# AT32UC3A4256S device description
Architecture: AVR32_UC3; Family: AVR UC3
Registers are 32-bit, read-write, reset 0x0 unless marked. A register's access mark holds for its fields unless they carry their own. Offsets are from the block's base; [hi:lo] are bit positions; {n}, {i} and the like mark numbered series.

## INTC — Interrupt Controller
Instances: INTC 0xFFFF0800
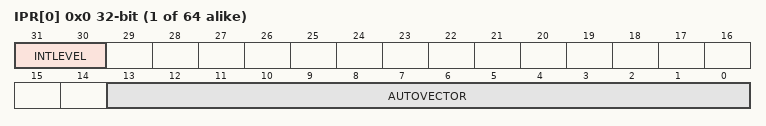
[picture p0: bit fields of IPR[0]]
{0x0+4i} IPR[{i}] (i=0..63) — Interrupt Priority Register
  [31:30] INTLEVEL — Interrupt Level
    {v}=INT{v} (v=0..3)
  [13:0] AUTOVECTOR — Handler offset
{0x100+4i} IRR[{i}] (i=0..63) ro — Interrupt Request Register
{0x200+4i} ICR[{i}] (i=0..3) ro — Interrupt Cause Register
  [5:0] CAUSE — Cause Group Number

## ADC — Analog to Digital Converter
Instances: ADC 0xffff3c00
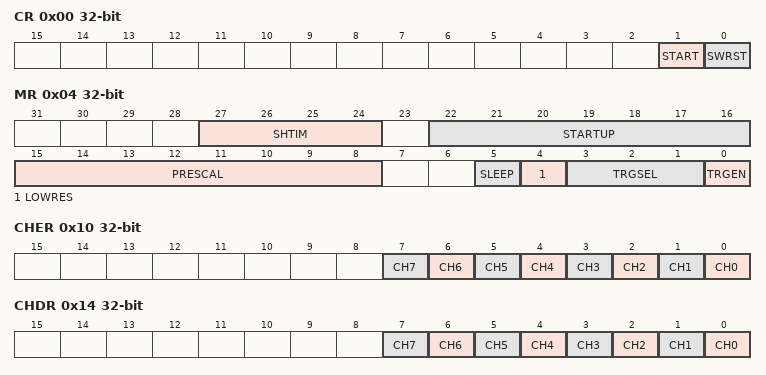
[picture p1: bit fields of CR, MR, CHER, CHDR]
0x00 CR wo reset not defined — Control Register
  [1] START — Start Conversion
  [0] SWRST — Software Reset
0x04 MR — Mode Register
  [27:24] SHTIM — Sample and Hold Time
  [22:16] STARTUP — Start Up Time
  [15:8] PRESCAL — Prescaler Rate Selection
  [5] SLEEP — Sleep Mode
  [4] LOWRES — Resolution
  [3:1] TRGSEL — Trigger Selection
  [0] TRGEN — Trigger Enable
0x10 CHER wo reset not defined — Channel Enable Register
  [n] CH{n} (n=0..7) — Channel {n} Enable
0x14 CHDR wo reset not defined — Channel Disable Register
  [n] CH{n} (n=0..7) — Channel {n} Disable
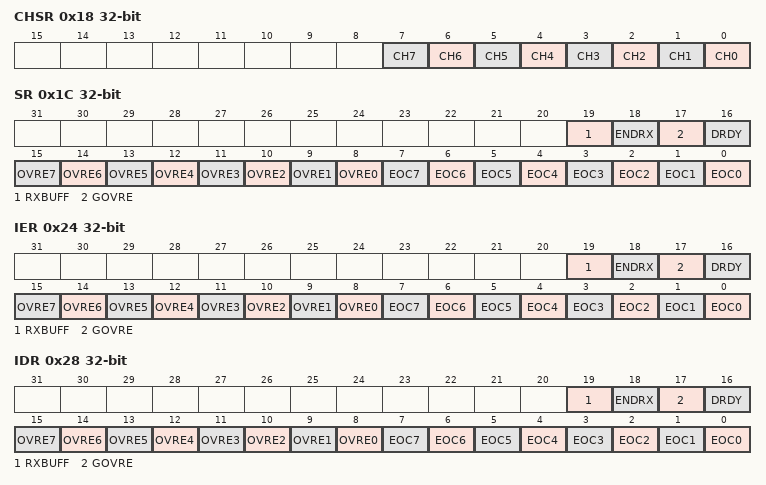
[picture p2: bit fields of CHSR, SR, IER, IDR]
0x18 CHSR ro — Channel Status Register
  [n] CH{n} (n=0..7)
0x1C SR ro reset not defined — Status Register
  [19] RXBUFF — RX Buffer Full
  [18] ENDRX — End of RX Buffer
  [17] GOVRE — General Overrun Error
  [16] DRDY — Data Ready
  [n+8] OVRE{n} (n=0..7) — Overrun Error {n}
  [n] EOC{n} (n=0..7) — End of Conversion {n}
0x20 LCDR ro reset not defined — Last Converted Data Register
  [9:0] LDATA — Last Data Converted
0x24 IER wo reset not defined — Interrupt Enable Register
  [19] RXBUFF — Receive Buffer Full Interrupt Enable
  [18] ENDRX — End of Receive Buffer Interrupt Enable
  [17] GOVRE — General Overrun Error Interrupt Enable
  [16] DRDY — Data Ready Interrupt Enable
  [n+8] OVRE{n} (n=0..7) — Overrun Error Interrupt Enable {n}
  [n] EOC{n} (n=0..7) — End of Conversion Interrupt Enable {n}
0x28 IDR wo reset not defined — Interrupt Disable Register
  [19] RXBUFF — Receive Buffer Full Interrupt Disable
  [18] ENDRX — End of Receive Buffer Interrupt Disable
  [17] GOVRE — General Overrun Interrupt Disable
  [16] DRDY — Data Ready Interrupt Disable
  [n+8] OVRE{n} (n=0..7) — Overrun Error Interrupt Disable {n}
  [n] EOC{n} (n=0..7) — End of Conversion Interrupt Disable {n}
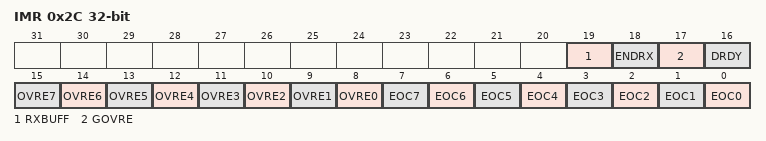
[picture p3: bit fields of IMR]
0x2C IMR ro — Interrupt Mask Register
  [19] RXBUFF — Receive Buffer Full Interrupt Mask
  [18] ENDRX — End of Receive Buffer Interrupt Mask
  [17] GOVRE — General Overrun Error Interrupt Mask
  [16] DRDY — Data Ready Interrupt Mask
  [n+8] OVRE{n} (n=0..7) — Overrun Error Interrupt Mask {n}
  [n] EOC{n} (n=0..7) — End of Conversion Interrupt Mask {n}
{0x30+4i} CDR{i} ro (i=0..7) — Channel Data Register {i}
  [9:0] DATA — Converted Data
0xFC VERSION ro reset not defined

## AES — Advanced Encryption Standard
Instances: AES 0xfffd0000
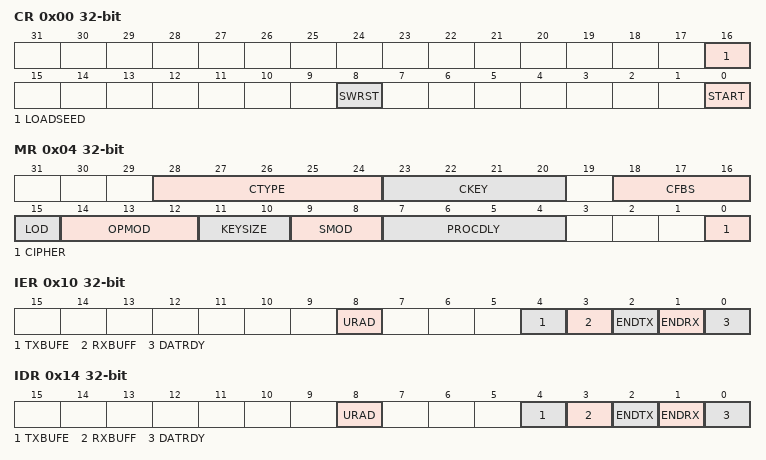
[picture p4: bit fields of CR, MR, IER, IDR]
0x00 CR wo reset not defined — Control Register
  [16] LOADSEED — Random Number Generator Seed Loading
  [8] SWRST — Software Reset
  [0] START — Start Processing
0x04 MR — Mode Register
  [28:24] CTYPE — Countermeasure Type
  [23:20] CKEY — Countermeasure Key
  [18:16] CFBS — Chiper Feedback Data Size
  [15] LOD — Last Output Data Mode
  [14:12] OPMOD — Operation Mode
  [11:10] KEYSIZE
  [9:8] SMOD — Start Mode
  [7:4] PROCDLY — Processing Delay
  [0] CIPHER — Processing Mode
0x10 IER wo reset not defined — Interrupt Enable Register
  [8] URAD — Unspecified Register Access Detection Interrupt Enable
  [4] TXBUFE — Receive Buffer Empty Interrupt Enable
  [3] RXBUFF — Receive Buffer Full Interrupt Enable
  [2] ENDTX — End of Transmit Buffer Interrupt Enable
  [1] ENDRX — End of Receive Buffer Interrupt Enable
  [0] DATRDY — Data Ready Interrupt Enable
0x14 IDR wo reset not defined — Interrupt Disable Register
  [8] URAD — Unspecified Register Access Detection Interrupt Disable
  [4] TXBUFE — Receive Buffer Empty Interrupt Disable
  [3] RXBUFF — Receive Buffer Full Interrupt Disable
  [2] ENDTX — End of Transmit Buffer Interrupt Disable
  [1] ENDRX — End of Receive Buffer Interrupt Disable
  [0] DATRDY — Data Ready Interrupt Disable
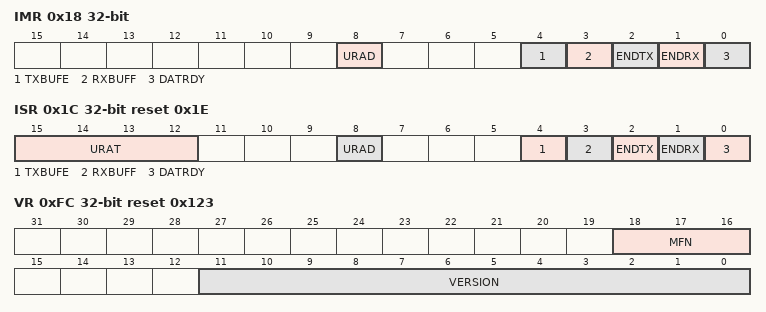
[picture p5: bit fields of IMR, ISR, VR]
0x18 IMR ro — Interrupt Mask Register
  [8] URAD — Unspecified Register Access Detection Interrupt Mask
  [4] TXBUFE — Receive Buffer Empty Interrupt Mask
  [3] RXBUFF — Receive Buffer Full Interrupt Mask
  [2] ENDTX — End of Transmit Buffer Interrupt Mask
  [1] ENDRX — End of Receive Buffer Interrupt Mask
  [0] DATRDY — Data Ready Interrupt Mask
0x1C ISR ro reset 0x1E — Interrupt Status Register
  [15:12] URAT — Unspecified Register Access Type
  [8] URAD — Unspecified Register Access Detection Status
  [4] TXBUFE — TX Buffer Empty
  [3] RXBUFF — RX Buffer Full
  [2] ENDTX — End of TX Buffer
  [1] ENDRX — End of RX Buffer
  [0] DATRDY — Data Ready
{0x1C+4i} KEYW{i}R wo reset not defined (i=1..8) — Key Word {i} Register
  [31:0] KEYWxR — AES Key Word x Register
0x40 IDATA1R wo reset not defined — Input Data 1 Register
  [31:0] IDATAx — Input Data Word x
0x44 IDATA2R wo reset not defined — Input Data 2 Register
  [31:0] IDATAx — Input Data Word x
0x48 IDATA3R wo reset not defined — Input Data 3 Register
  [31:0] IDATAx
0x4C IDATA4R wo reset not defined — Input Data 4 Register
  [31:0] IDATAx
0x50 ODATA1R ro — Output Data 1 Register
  [31:0] ODATAxR — AES Output Data x Register
0x54 ODATA2R ro reset 0xC01F0000 — Output Data 2 Register
  [31:0] ODATAxR — AES Output Data x Register
0x58 ODATA3R ro — Output Data 3 Register
  [31:0] ODATAxR — AES Output Data x Register
0x5C ODATA4R ro — Output Data 4 Register
  [31:0] ODATAxR — AES Output Data x Register
{0x5C+4i} IV{i}R wo reset not defined (i=1..3) — Initialization Vector {i} Register
  [31:0] IVxR — AES Initialization Vector x Register
0x6C IV4E wo reset not defined — Initialization Vector 4 Register
  [31:0] IVxR — AES Initialization Vector x Register
0xFC VR ro reset 0x123 — AES version
  [18:16] MFN — Metal fix number
  [11:0] VERSION — AES version
